# LargeDummyDevice register map
File version: 1.0
Registers are 32-bit, read-write, no defined reset value unless marked. A register's access mark holds for its fields unless they carry their own. Offsets are from the block's base; [hi:lo] are bit positions.

## PERIPHERAL_90
Base 0x40059000
0x04 REG_1 — Register 1
  [31] FIELD_24, [29:27] FIELD_16, [30:27] FIELD_22, [29:25] FIELD_5, [28:25] FIELD_23, [22:21] FIELD_12, [21:19] FIELD_10, [20:19] FIELD_14, [20:18] FIELD_4, [19:17] FIELD_13, [19:15] FIELD_15, [15:14] FIELD_1, [16:13] FIELD_3, [15:12] FIELD_9, [12:11] FIELD_7, [12:10] FIELD_18, [13:10] FIELD_25, [13:9] FIELD_17, [12:9] FIELD_21, [9:7] FIELD_20, [7:6] FIELD_11, [7:4] FIELD_2, [3] FIELD_6, [4:2] FIELD_26, [4:1] FIELD_8, [4:1] FIELD_19, [4:0] FIELD_27
0x08 REG_2 — Register 2
  [34:31] FIELD_8, [30] FIELD_3, [30:28] FIELD_14, [30:26] FIELD_15, [23:22] FIELD_7, [23:19] FIELD_1, [17:16] FIELD_16, [19:15] FIELD_6, [17:15] FIELD_11, [15:14] FIELD_2, [14] FIELD_10, [13:9] FIELD_4, [12:9] FIELD_13, [9:7] FIELD_12, [5] FIELD_9, [8:4] FIELD_5
0x0C REG_3 — Register 3
  [34:31] FIELD_1, [28:25] FIELD_3, [17:13] FIELD_2
0x10 REG_4 — Register 4
  [31:30] FIELD_6, [31:28] FIELD_13, [30:27] FIELD_3, [31:27] FIELD_8, [29:26] FIELD_1, [29:26] FIELD_10, [24:23] FIELD_19, [23] FIELD_21, [25:22] FIELD_14, [20:18] FIELD_20, [18:17] FIELD_16, [17:15] FIELD_22, [15:14] FIELD_7, [16:13] FIELD_2, [14:11] FIELD_4, [8] FIELD_11, [7:6] FIELD_5, [9:6] FIELD_9, [7:4] FIELD_18, [7:3] FIELD_15, [6:3] FIELD_17, [0] FIELD_12
0x14 REG_5 — Register 5
  [32:31] FIELD_4, [30:29] FIELD_2, [24:21] FIELD_5, [21:19] FIELD_1, [22:19] FIELD_6, [17] FIELD_11, [16:13] FIELD_7, [15:12] FIELD_8, [11] FIELD_9, [9] FIELD_10, [2] FIELD_3
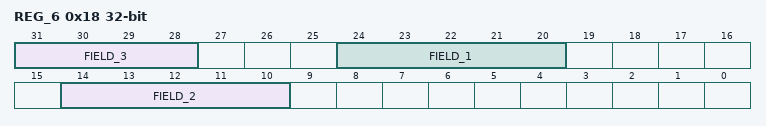
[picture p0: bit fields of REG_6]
0x18 REG_6 — Register 6
  [31:28] FIELD_3, [24:20] FIELD_1, [14:10] FIELD_2
0x1C REG_7 — Register 7
  [27:24] FIELD_1, [25:23] FIELD_5, [12] FIELD_4, [12:8] FIELD_3, [7:4] FIELD_2
0x20 REG_8 — Register 8
  [31:27] FIELD_1, [26:22] FIELD_5, [22] FIELD_6, [23:20] FIELD_9, [18:16] FIELD_2, [19:16] FIELD_3, [18:15] FIELD_8, [7:6] FIELD_7, [4:2] FIELD_4
0x24 REG_9 — Register 9
  [35:31] FIELD_8, [30:29] FIELD_3, [32:28] FIELD_4, [29:28] FIELD_31, [28:24] FIELD_19, [26:23] FIELD_21, [25:23] FIELD_27, [22] FIELD_2, [25:22] FIELD_5, [25:22] FIELD_15, [24:22] FIELD_29, [24:21] FIELD_10, [21] FIELD_14, [22:21] FIELD_32, [20] FIELD_24, [22:19] FIELD_9, [19:16] FIELD_17, [15:14] FIELD_16, [14:10] FIELD_23, [11:9] FIELD_12, [13:9] FIELD_18, [11:9] FIELD_22, [9:7] FIELD_20, [7:6] FIELD_1, [8:5] FIELD_13, [7:5] FIELD_25, [5] FIELD_26, [7:5] FIELD_30, [3] FIELD_7, [5:1] FIELD_6, [2:1] FIELD_28, [3:0] FIELD_11
0x28 REG_10 — Register 10
  [33:30] FIELD_11, [32:30] FIELD_21, [29] FIELD_6, [30:29] FIELD_8, [27:26] FIELD_4, [30:26] FIELD_12, [29:26] FIELD_25, [29:25] FIELD_22, [24] FIELD_3, [25:24] FIELD_18, [26:22] FIELD_10, [22] FIELD_13, [19:18] FIELD_19, [21:18] FIELD_26, [19:17] FIELD_9, [17:15] FIELD_7, [14:13] FIELD_17, [14:13] FIELD_28, [14:12] FIELD_29, [7] FIELD_2, [10:7] FIELD_5, [9:7] FIELD_16, [9:6] FIELD_20, [9:6] FIELD_24, [10:6] FIELD_27, [8:4] FIELD_14, [5:3] FIELD_15, [2] FIELD_1, [5:1] FIELD_23
0x2C REG_11 — Register 11
  [29:28] FIELD_2, [30:28] FIELD_6, [27:26] FIELD_5, [22] FIELD_7, [24:22] FIELD_8, [23:21] FIELD_3, [21:20] FIELD_9, [22:18] FIELD_1, [12:10] FIELD_10, [10:7] FIELD_4
0x30 REG_12 — Register 12
  [31:30] FIELD_15, [29:28] FIELD_3, [32:28] FIELD_10, [27] FIELD_17, [30:26] FIELD_4, [25] FIELD_11, [25:23] FIELD_1, [23] FIELD_14, [26:22] FIELD_16, [25:21] FIELD_19, [20:19] FIELD_7, [21:19] FIELD_21, [18] FIELD_13, [20:18] FIELD_23, [17] FIELD_5, [16:13] FIELD_8, [12:11] FIELD_2, [13:11] FIELD_9, [12:11] FIELD_18, [9:8] FIELD_12, [5:3] FIELD_6, [5:2] FIELD_20, [6:2] FIELD_22, [4:2] FIELD_24, [3:2] FIELD_25
0x34 REG_13 — Register 13
  [33:31] FIELD_6, [28] FIELD_5, [30:27] FIELD_21, [28:26] FIELD_13, [28:25] FIELD_3, [29:25] FIELD_20, [26:23] FIELD_18, [24:22] FIELD_4, [20] FIELD_15, [18:17] FIELD_26, [17:16] FIELD_22, [16:15] FIELD_10, [17:15] FIELD_12, [17:13] FIELD_8, [14:11] FIELD_17, [15:11] FIELD_23, [13:10] FIELD_11, [11:9] FIELD_9, [12:9] FIELD_14, [5:4] FIELD_1, [4:1] FIELD_7, [1] FIELD_19, [3:1] FIELD_24, [4:1] FIELD_25, [2:0] FIELD_2, [0] FIELD_16
0x38 REG_14 — Register 14
  [34:30] FIELD_3, [32:28] FIELD_11, [28:27] FIELD_1, [30:26] FIELD_5, [27:26] FIELD_9, [27:25] FIELD_4, [29:25] FIELD_12, [27:24] FIELD_10, [23:22] FIELD_2, [21] FIELD_6, [9:7] FIELD_8, [9:6] FIELD_14, [6:5] FIELD_15, [6:2] FIELD_13, [3:1] FIELD_7
0x3C REG_15 — Register 15
  [33:31] FIELD_8, [32:31] FIELD_17, [33:30] FIELD_6, [30] FIELD_7, [32:30] FIELD_16, [33:29] FIELD_19, [29:28] FIELD_11, [28] FIELD_27, [25:23] FIELD_5, [26:23] FIELD_9, [25:21] FIELD_26, [19] FIELD_1, [18] FIELD_4, [20:18] FIELD_22, [18:16] FIELD_13, [20:16] FIELD_14, [18:16] FIELD_20, [19:15] FIELD_21, [15:14] FIELD_3, [15:14] FIELD_15, [13] FIELD_25, [14:12] FIELD_18, [16:12] FIELD_24, [8] FIELD_2, [8:6] FIELD_23, [7:5] FIELD_12, [3:0] FIELD_10
0x40 REG_16 — Register 16
  [9:6] FIELD_1
0x44 REG_17 — Register 17
  [31:29] FIELD_22, [32:28] FIELD_20, [27:24] FIELD_10, [24:23] FIELD_8, [27:23] FIELD_19, [23:22] FIELD_13, [24:22] FIELD_18, [23:21] FIELD_2, [22:20] FIELD_31, [22:19] FIELD_16, [22:19] FIELD_23, [21:18] FIELD_12, [18] FIELD_26, [16:15] FIELD_7, [17:15] FIELD_21, [15:14] FIELD_3, [15:14] FIELD_15, [15:13] FIELD_1, [17:13] FIELD_5, [14:13] FIELD_17, [14:11] FIELD_9, [14:11] FIELD_30, [13:9] FIELD_6, [11:8] FIELD_4, [8:7] FIELD_24, [11:7] FIELD_29, [8:6] FIELD_25, [5] FIELD_14, [8:4] FIELD_28, [5:3] FIELD_11, [5:2] FIELD_27
0x48 REG_18 — Register 18
  [31:30] FIELD_27, [31:27] FIELD_1, [29:27] FIELD_4, [29:27] FIELD_15, [28:25] FIELD_21, [24:22] FIELD_8, [23:22] FIELD_16, [26:22] FIELD_26, [23:20] FIELD_18, [22:19] FIELD_17, [21:19] FIELD_20, [20:18] FIELD_14, [18:15] FIELD_5, [17:13] FIELD_12, [14:12] FIELD_19, [14:11] FIELD_9, [14:11] FIELD_24, [12:10] FIELD_7, [13:9] FIELD_2, [13:9] FIELD_3, [12:9] FIELD_6, [8] FIELD_22, [9:8] FIELD_25, [9:7] FIELD_11, [9:6] FIELD_10, [6:3] FIELD_13, [4:0] FIELD_23
0x4C REG_19 — Register 19
  [33:31] FIELD_10, [32:29] FIELD_2, [28:27] FIELD_1, [27] FIELD_12, [26] FIELD_3, [27:24] FIELD_6, [25:24] FIELD_9, [24] FIELD_14, [27:24] FIELD_20, [27:23] FIELD_17, [23] FIELD_19, [23:21] FIELD_4, [25:21] FIELD_21, [20:19] FIELD_18, [19:16] FIELD_13, [13:12] FIELD_7, [9:8] FIELD_15, [7] FIELD_8, [8:6] FIELD_11, [4] FIELD_5, [1:0] FIELD_16
0x50 REG_20 — Register 20
  [31:29] FIELD_14, [31:29] FIELD_26, [30:27] FIELD_7, [28:27] FIELD_18, [27:26] FIELD_1, [23] FIELD_24, [24:21] FIELD_28, [21:19] FIELD_4, [19:18] FIELD_2, [20:18] FIELD_8, [18:17] FIELD_23, [20:16] FIELD_22, [15:14] FIELD_15, [17:13] FIELD_13, [17:13] FIELD_19, [15:12] FIELD_5, [11] FIELD_12, [13:9] FIELD_9, [12:8] FIELD_3, [10:6] FIELD_27, [9:5] FIELD_11, [5] FIELD_17, [5:4] FIELD_16, [4] FIELD_25, [5:1] FIELD_10, [3:1] FIELD_20, [1] FIELD_21, [4:0] FIELD_6
0x54 REG_21 — Register 21
  [35:31] FIELD_1, [33:29] FIELD_7, [30:27] FIELD_8, [24:22] FIELD_9, [22:18] FIELD_5, [20:16] FIELD_11, [17:15] FIELD_12, [15:14] FIELD_2, [12] FIELD_4, [9] FIELD_10, [2] FIELD_6, [1] FIELD_3
0x58 REG_22 — Register 22
  [33:29] FIELD_9, [28:27] FIELD_7, [22:20] FIELD_3, [19:18] FIELD_2, [18:17] FIELD_4, [18:14] FIELD_1, [17:13] FIELD_8, [13:9] FIELD_5, [11:7] FIELD_10, [8:4] FIELD_6
0x5C REG_23 — Register 23
  [30] FIELD_13, [30:29] FIELD_7, [30:29] FIELD_29, [29:26] FIELD_4, [26] FIELD_6, [29:25] FIELD_15, [28:25] FIELD_16, [26:25] FIELD_17, [25] FIELD_20, [24] FIELD_1, [28:24] FIELD_25, [24:22] FIELD_2, [23:22] FIELD_10, [20] FIELD_14, [21:19] FIELD_18, [20:19] FIELD_26, [17:16] FIELD_22, [18:14] FIELD_5, [15:13] FIELD_23, [16:12] FIELD_27, [13:11] FIELD_19, [7] FIELD_24, [10:7] FIELD_28, [7:5] FIELD_8, [5] FIELD_12, [6:3] FIELD_9, [3:1] FIELD_3, [0] FIELD_11, [3:0] FIELD_21
0x60 REG_24 — Register 24
  [31:30] FIELD_13, [29:28] FIELD_6, [28:27] FIELD_10, [28:24] FIELD_3, [24] FIELD_14, [27:23] FIELD_1, [25:22] FIELD_4, [22:20] FIELD_5, [19:18] FIELD_15, [17:15] FIELD_11, [16:12] FIELD_8, [9] FIELD_7, [8:5] FIELD_2, [9:5] FIELD_9, [5:4] FIELD_12
0x64 REG_25 — Register 25
  [35:31] FIELD_1, [32:29] FIELD_9, [30:27] FIELD_2, [30:27] FIELD_20, [29:26] FIELD_8, [26] FIELD_30, [27:23] FIELD_4, [25:23] FIELD_10, [26:23] FIELD_15, [25:23] FIELD_25, [24:22] FIELD_17, [25:21] FIELD_11, [21:20] FIELD_14, [21:18] FIELD_16, [18] FIELD_22, [11] FIELD_21, [12:9] FIELD_24, [11:9] FIELD_28, [7] FIELD_19, [6:5] FIELD_3, [7:5] FIELD_7, [5] FIELD_26, [5] FIELD_29, [4] FIELD_6, [5:4] FIELD_23, [3] FIELD_13, [2] FIELD_18, [2:0] FIELD_5, [2:0] FIELD_12, [4:0] FIELD_27
0x68 REG_26 — Register 26
  [31:29] FIELD_5, [30:28] FIELD_2, [32:28] FIELD_8, [31:28] FIELD_9, [23:22] FIELD_11, [20:19] FIELD_3, [18:16] FIELD_6, [13:12] FIELD_4, [13:10] FIELD_1, [12:10] FIELD_7, [10:6] FIELD_10
0x6C REG_27 — Register 27
  [25:24] FIELD_5, [22:21] FIELD_6, [23:20] FIELD_7, [22:18] FIELD_3, [7] FIELD_2, [4] FIELD_1, [7:3] FIELD_4
0x70 REG_28 — Register 28
  [31] FIELD_2, [35:31] FIELD_13, [34:30] FIELD_9, [33:30] FIELD_17, [30] FIELD_27, [30:26] FIELD_4, [29:25] FIELD_23, [24] FIELD_1, [27:24] FIELD_6, [24] FIELD_14, [26:24] FIELD_19, [26:24] FIELD_24, [24:23] FIELD_5, [27:23] FIELD_18, [20:18] FIELD_22, [20:17] FIELD_16, [18:15] FIELD_11, [14] FIELD_12, [18:14] FIELD_28, [14:13] FIELD_21, [15:12] FIELD_8, [14:11] FIELD_15, [11:8] FIELD_20, [10:6] FIELD_7, [7:6] FIELD_25, [7:4] FIELD_3, [3:1] FIELD_26, [2:0] FIELD_10, [4:0] FIELD_29
0x74 REG_29 — Register 29
  [33:31] FIELD_6, [30] FIELD_22, [29] FIELD_19, [29:28] FIELD_2, [32:28] FIELD_7, [32:28] FIELD_12, [22] FIELD_16, [21:20] FIELD_5, [21:20] FIELD_11, [23:20] FIELD_13, [22:18] FIELD_4, [19:18] FIELD_20, [19:18] FIELD_25, [20:16] FIELD_9, [18:16] FIELD_24, [15] FIELD_23, [13:12] FIELD_1, [12] FIELD_14, [11:9] FIELD_26, [8] FIELD_18, [7] FIELD_3, [11:7] FIELD_10, [11:7] FIELD_15, [7] FIELD_21, [6:5] FIELD_17, [6:4] FIELD_8
0x78 REG_30 — Register 30
  [34:31] FIELD_12, [32:29] FIELD_7, [31:29] FIELD_14, [29:27] FIELD_15, [24] FIELD_5, [27:24] FIELD_13, [25:23] FIELD_9, [20:19] FIELD_8, [21:18] FIELD_11, [17:14] FIELD_6, [15:11] FIELD_10, [14:10] FIELD_1, [12:9] FIELD_2, [9:8] FIELD_3, [8:4] FIELD_4
0x7C REG_31 — Register 31
  [33:31] FIELD_12, [32:31] FIELD_13, [28:24] FIELD_17, [23:22] FIELD_4, [25:22] FIELD_6, [23:20] FIELD_3, [23:20] FIELD_16, [21:20] FIELD_19, [20:17] FIELD_9, [19:16] FIELD_2, [18:16] FIELD_14, [18:14] FIELD_5, [14:12] FIELD_11, [10:9] FIELD_8, [10:6] FIELD_7, [7:4] FIELD_15, [4:3] FIELD_18, [5:2] FIELD_10, [1:0] FIELD_1
0x80 REG_32 — Register 32
  [34:31] FIELD_4, [31:29] FIELD_5, [28] FIELD_6, [31:27] FIELD_12, [30:26] FIELD_7, [26:25] FIELD_1, [10:9] FIELD_8, [11:8] FIELD_9, [6:5] FIELD_10, [6:5] FIELD_11, [6:2] FIELD_3, [3:0] FIELD_2
0x84 REG_33 — Register 33
  [33:30] FIELD_19, [31:28] FIELD_4, [31:27] FIELD_13, [26] FIELD_5, [29:25] FIELD_18, [27:24] FIELD_9, [25:22] FIELD_8, [26:22] FIELD_10, [23:22] FIELD_11, [21:19] FIELD_1, [21:19] FIELD_3, [21:19] FIELD_20, [18] FIELD_6, [15:14] FIELD_2, [16:14] FIELD_17, [14:12] FIELD_7, [11:8] FIELD_16, [9:7] FIELD_14, [8:4] FIELD_15, [5:1] FIELD_12
0x88 REG_34 — Register 34
  [35:31] FIELD_2, [30:29] FIELD_3, [15:12] FIELD_1, [13:9] FIELD_4
0x8C REG_35 — Register 35
  [31] FIELD_5, [34:31] FIELD_16, [31] FIELD_19, [34:31] FIELD_23, [31:29] FIELD_6, [33:29] FIELD_10, [30:27] FIELD_8, [26:25] FIELD_7, [28:25] FIELD_14, [26:24] FIELD_4, [25:24] FIELD_21, [27:24] FIELD_25, [26:24] FIELD_26, [26:22] FIELD_18, [17] FIELD_1, [20:17] FIELD_22, [16:15] FIELD_15, [14] FIELD_3, [17:14] FIELD_12, [15:13] FIELD_28, [16:12] FIELD_17, [11:9] FIELD_13, [11:7] FIELD_9, [7] FIELD_11, [8:7] FIELD_20, [2] FIELD_2, [3:2] FIELD_24, [3:2] FIELD_27
0x90 REG_36 — Register 36
  [30] FIELD_2, [28] FIELD_6, [29:25] FIELD_3, [28:24] FIELD_4, [26:23] FIELD_11, [22] FIELD_5, [22] FIELD_12, [23:22] FIELD_14, [22:21] FIELD_9, [20:19] FIELD_1, [16] FIELD_15, [17:14] FIELD_18, [12] FIELD_7, [15:12] FIELD_20, [11:10] FIELD_16, [14:10] FIELD_19, [10:9] FIELD_17, [10:8] FIELD_8, [10:8] FIELD_10, [7] FIELD_21, [3:1] FIELD_13
